VERSION ""

NS_ :

BS_:

BU_: ESP PDM C50 ATCCR ATCCF

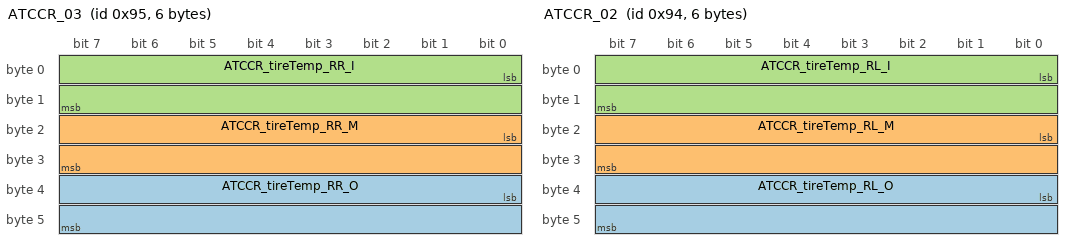
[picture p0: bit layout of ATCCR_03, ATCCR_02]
BO_ 149 ATCCR_03: 6 Vector__XXX
 SG_ ATCCR_tireTemp_RR_O : 32|16@1- (0.1,0) [-50|200] "" Vector__XXX
 SG_ ATCCR_tireTemp_RR_M : 16|16@1- (0.1,0) [-50|200] "" Vector__XXX
 SG_ ATCCR_tireTemp_RR_I : 0|16@1- (0.1,0) [-50|200] "" Vector__XXX

BO_ 148 ATCCR_02: 6 Vector__XXX
 SG_ ATCCR_tireTemp_RL_O : 32|16@1- (0.1,0) [-50|200] "" Vector__XXX
 SG_ ATCCR_tireTemp_RL_M : 16|16@1- (0.1,0) [-50|200] "" Vector__XXX
 SG_ ATCCR_tireTemp_RL_I : 0|16@1- (0.1,0) [-50|200] "" Vector__XXX

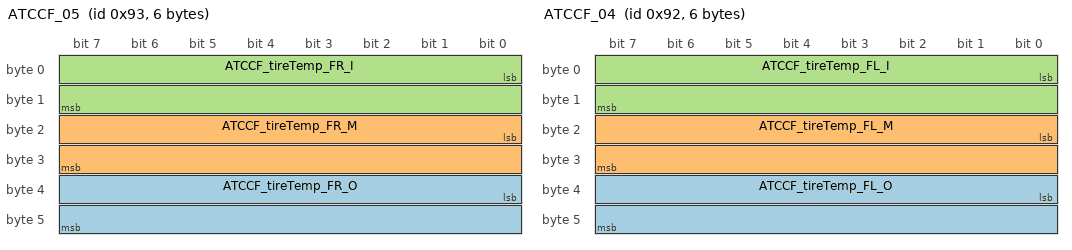
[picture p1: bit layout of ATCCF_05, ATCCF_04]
BO_ 147 ATCCF_05: 6 Vector__XXX
 SG_ ATCCF_tireTemp_FR_O : 32|16@1- (0.1,0) [-50|200] "" Vector__XXX
 SG_ ATCCF_tireTemp_FR_M : 16|16@1- (0.1,0) [-50|200] "" Vector__XXX
 SG_ ATCCF_tireTemp_FR_I : 0|16@1- (0.1,0) [-50|200] "" Vector__XXX

BO_ 146 ATCCF_04: 6 Vector__XXX
 SG_ ATCCF_tireTemp_FL_O : 32|16@1- (0.1,0) [-50|200] "" Vector__XXX
 SG_ ATCCF_tireTemp_FL_M : 16|16@1- (0.1,0) [-50|200] "" Vector__XXX
 SG_ ATCCF_tireTemp_FL_I : 0|16@1- (0.1,0) [-50|200] "" Vector__XXX

CM_ BU_ ESP "Bosch ESP Unit";
CM_ BU_ PDM "Power Distrubution Module";
CM_ BU_ C50 "C50 Data Logger";
CM_ BU_ ATCCR "The Rear Analog To CAN Converter";
CM_ BU_ ATCCF "Front Analog To CAN Converter";
BA_DEF_  "BusType" STRING ;
BA_DEF_DEF_  "BusType" "CAN";
